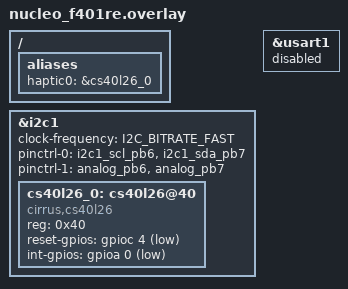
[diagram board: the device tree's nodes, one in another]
/*
 * Copyright (c) 2026 Cirrus Logic, Inc.
 *
 * SPDX-License-Identifier: Apache-2.0
 */

#include <zephyr/dt-bindings/i2c/i2c.h>

/ {
	aliases {
		haptic0 = &cs40l26_0;
	};
};

&i2c1 {
	status = "okay";

	clock-frequency = <I2C_BITRATE_FAST>;

	pinctrl-0 = <&i2c1_scl_pb6 &i2c1_sda_pb7>;
	pinctrl-1 = <&analog_pb6 &analog_pb7>;
	pinctrl-names = "default", "sleep";

	cs40l26_0: cs40l26@40 {
		compatible = "cirrus,cs40l26";
		reg = <0x40>;

		reset-gpios = <&gpioc 4 (GPIO_ACTIVE_LOW | GPIO_PULL_UP)>;
		int-gpios = <&gpioa 0 (GPIO_ACTIVE_LOW | GPIO_PULL_UP)>;

		status = "okay";
	};
};

&usart1 {
	status = "disabled";
};
